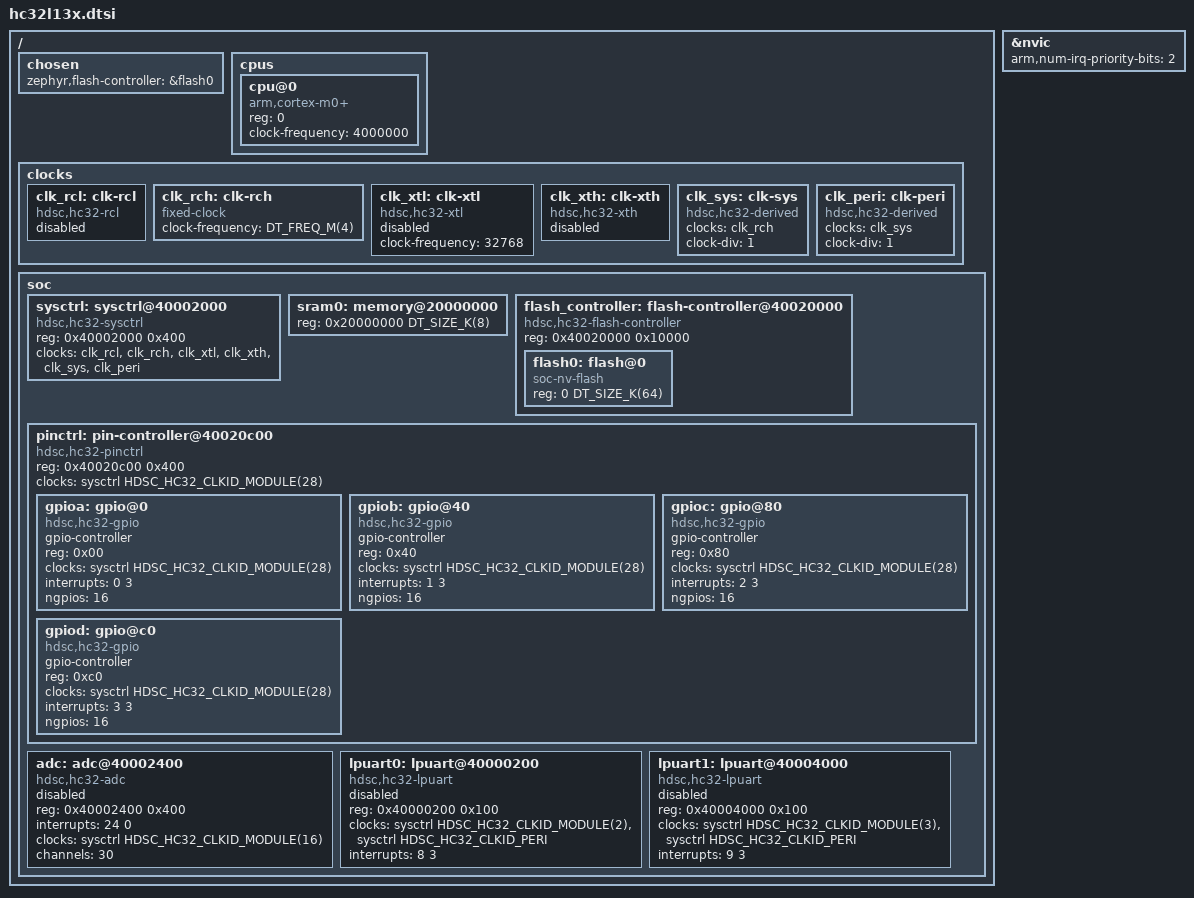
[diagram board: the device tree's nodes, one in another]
#include <arm/armv6-m.dtsi>
#include <freq.h>
#include <mem.h>

#include <zephyr/dt-bindings/clock/hdsc_hc32_clock.h>

/ {
	chosen {
		zephyr,flash-controller = &flash0;
	};

	cpus {
		#address-cells = <1>;
		#size-cells = <0>;

		cpu@0 {
			device_type = "cpu";
			compatible = "arm,cortex-m0+";
			reg = <0>;
			clock-frequency = <4000000>;
		};
	};

	clocks {
		clk_rcl: clk-rcl {
			compatible = "hdsc,hc32-rcl";
			#clock-cells = <0>;
			status = "disabled";
		};

		clk_rch: clk-rch {
			compatible = "fixed-clock";
			clock-frequency = <DT_FREQ_M(4)>;
			#clock-cells = <0>;
			status = "okay";
		};

		clk_xtl: clk-xtl {
			compatible = "hdsc,hc32-xtl";
			clock-frequency = <32768>;
			#clock-cells = <0>;
			status = "disabled";
		};

		clk_xth: clk-xth {
			compatible = "hdsc,hc32-xth";
			#clock-cells = <0>;
			status = "disabled";
		};

		clk_sys: clk-sys {
			compatible = "hdsc,hc32-derived";
			#clock-cells = <0>;
			clocks = <&clk_rch>;
			clock-div = <1>;
		};

		clk_peri: clk-peri {
			compatible = "hdsc,hc32-derived";
			#clock-cells = <0>;
			clocks = <&clk_sys>;
			clock-div = <1>;
		};
	};

	soc {
		sysctrl: sysctrl@40002000 {
			compatible = "hdsc,hc32-sysctrl";
			reg = <0x40002000 0x400>;
			#clock-cells = <1>;
			clocks = <&clk_rcl>, <&clk_rch>, <&clk_xtl>, <&clk_xth>, <&clk_sys>,
				 <&clk_peri>;
			clock-names = "rcl", "rch", "xtl", "xth", "sys", "peri";
			status = "okay";
		};

		sram0: memory@20000000 {
			reg = <0x20000000 DT_SIZE_K(8)>;
		};

		flash_controller: flash-controller@40020000 {
			compatible = "hdsc,hc32-flash-controller";
			reg = <0x40020000 0x10000>;

			#address-cells = <1>;
			#size-cells = <1>;

			flash0: flash@0 {
				compatible = "soc-nv-flash";
				reg = <0 DT_SIZE_K(64)>;
			};
		};

		pinctrl: pin-controller@40020c00 {
			compatible = "hdsc,hc32-pinctrl";
			#address-cells = <1>;
			#size-cells = <0>;
			reg = <0x40020c00 0x400>;
			clocks = <&sysctrl HDSC_HC32_CLKID_MODULE(28)>;

			gpioa: gpio@0 {
				compatible = "hdsc,hc32-gpio";
				gpio-controller;
				#gpio-cells = <2>;
				reg = <0x00>;
				clocks = <&sysctrl HDSC_HC32_CLKID_MODULE(28)>;
				interrupts = <0 3>;
				ngpios = <16>;
			};

			gpiob: gpio@40 {
				compatible = "hdsc,hc32-gpio";
				gpio-controller;
				#gpio-cells = <2>;
				reg = <0x40>;
				clocks = <&sysctrl HDSC_HC32_CLKID_MODULE(28)>;
				interrupts = <1 3>;
				ngpios = <16>;
			};

			gpioc: gpio@80 {
				compatible = "hdsc,hc32-gpio";
				gpio-controller;
				#gpio-cells = <2>;
				reg = <0x80>;
				clocks = <&sysctrl HDSC_HC32_CLKID_MODULE(28)>;
				interrupts = <2 3>;
				ngpios = <16>;
			};

			gpiod: gpio@c0 {
				compatible = "hdsc,hc32-gpio";
				gpio-controller;
				#gpio-cells = <2>;
				reg = <0xc0>;
				clocks = <&sysctrl HDSC_HC32_CLKID_MODULE(28)>;
				interrupts = <3 3>;
				ngpios = <16>;
			};

		};

		adc: adc@40002400 {
			compatible = "hdsc,hc32-adc";
			reg = <0x40002400 0x400>;
			interrupts = <24 0>;
			clocks = <&sysctrl HDSC_HC32_CLKID_MODULE(16)>;
			channels = <30>;
			status = "disabled";
			#io-channel-cells = <1>;
		};

		lpuart0: lpuart@40000200 {
			compatible = "hdsc,hc32-lpuart";
			reg = <0x40000200 0x100>;
			clocks = <&sysctrl HDSC_HC32_CLKID_MODULE(2)>, <&sysctrl HDSC_HC32_CLKID_PERI>;
			clock-names = "module", "tx";
			interrupts = <8 3>;
			status = "disabled";
		};

		lpuart1: lpuart@40004000 {
			compatible = "hdsc,hc32-lpuart";
			reg = <0x40004000 0x100>;
			clocks = <&sysctrl HDSC_HC32_CLKID_MODULE(3)>, <&sysctrl HDSC_HC32_CLKID_PERI>;
			clock-names = "module", "tx";
			interrupts = <9 3>;
			status = "disabled";
		};
	};
};

&nvic {
	arm,num-irq-priority-bits = <2>;
};
